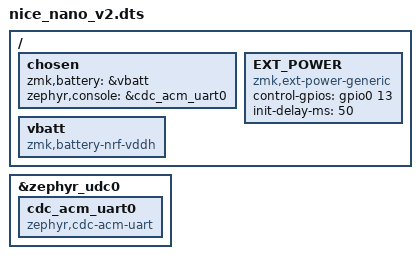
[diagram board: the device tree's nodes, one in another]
/*
 * Copyright (c) 2021 The ZMK Contributors
 *
 * SPDX-License-Identifier: MIT
 */

/dts-v1/;
#include "nice_nano.dtsi"

/ {
    chosen {
        zmk,battery = &vbatt;
		zephyr,console = &cdc_acm_uart0;
    };

    // Node name must match original "EXT_POWER" label to preserve user settings.
    EXT_POWER {
        compatible = "zmk,ext-power-generic";
        control-gpios = <&gpio0 13 GPIO_ACTIVE_HIGH>;
        init-delay-ms = <50>;
    };

    vbatt: vbatt {
        compatible = "zmk,battery-nrf-vddh";
    };
};

&zephyr_udc0 {
	cdc_acm_uart0: cdc_acm_uart0 {
		compatible = "zephyr,cdc-acm-uart";
	};
};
